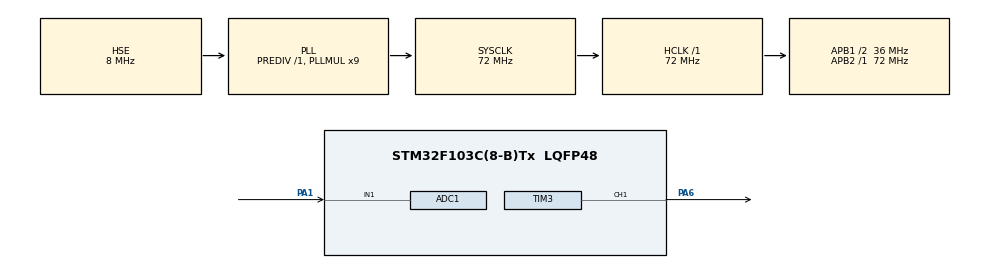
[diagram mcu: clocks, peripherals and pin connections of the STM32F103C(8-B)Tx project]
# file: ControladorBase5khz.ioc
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ADC1.Channel-1\#ChannelRegularConversion=ADC_CHANNEL_1
ADC1.ExternalTrigConv=ADC_EXTERNALTRIGCONV_T3_TRGO
ADC1.NbrOfConversionFlag=1
ADC1.Rank-1\#ChannelRegularConversion=1
ADC1.SamplingTime-1\#ChannelRegularConversion=ADC_SAMPLETIME_13CYCLES_5
ADC1.master=1
Dma.ADC1.1.Direction=DMA_PERIPH_TO_MEMORY
Dma.ADC1.1.Instance=DMA1_Channel1
Dma.ADC1.1.MemDataAlignment=DMA_MDATAALIGN_HALFWORD
Dma.ADC1.1.MemInc=DMA_MINC_ENABLE
Dma.ADC1.1.Mode=DMA_CIRCULAR
Dma.ADC1.1.PeriphDataAlignment=DMA_PDATAALIGN_HALFWORD
Dma.ADC1.1.PeriphInc=DMA_PINC_DISABLE
Dma.ADC1.1.Priority=DMA_PRIORITY_LOW
Dma.Request0=TIM3_CH1/TRIG
Dma.Request1=ADC1
Dma.TIM3_CH1/TRIG.0.Direction=DMA_MEMORY_TO_PERIPH
Dma.TIM3_CH1/TRIG.0.Instance=DMA1_Channel6
Dma.TIM3_CH1/TRIG.0.MemDataAlignment=DMA_MDATAALIGN_HALFWORD
Dma.TIM3_CH1/TRIG.0.MemInc=DMA_MINC_ENABLE
Dma.TIM3_CH1/TRIG.0.Mode=DMA_CIRCULAR
Dma.TIM3_CH1/TRIG.0.PeriphDataAlignment=DMA_PDATAALIGN_HALFWORD
Dma.TIM3_CH1/TRIG.0.PeriphInc=DMA_PINC_DISABLE
Dma.TIM3_CH1/TRIG.0.Priority=DMA_PRIORITY_LOW
Mcu.Family=STM32F1
Mcu.Name=STM32F103C(8-B)Tx
Mcu.Package=LQFP48
NVIC.DMA1_Channel1_IRQn=true\:0\:0\:false\:false\:true\:false\:true\:true
NVIC.DMA1_Channel6_IRQn=true\:0\:0\:false\:false\:true\:false\:true\:true
NVIC.PriorityGroup=NVIC_PRIORITYGROUP_4
PA1.Signal=ADCx_IN1
PA13.Mode=Serial_Wire
PA13.Signal=SYS_JTMS-SWDIO
PA14.Mode=Serial_Wire
PA14.Signal=SYS_JTCK-SWCLK
PA6.Signal=S_TIM3_CH1
PD0-OSC_IN.Mode=HSE-External-Oscillator
PD0-OSC_IN.Signal=RCC_OSC_IN
PD1-OSC_OUT.Mode=HSE-External-Oscillator
PD1-OSC_OUT.Signal=RCC_OSC_OUT
ProjectManager.HeapSize=0x200
ProjectManager.StackSize=0x400
ProjectManager.TargetToolchain=CMake
RCC.ADCPresc=RCC_ADCPCLK2_DIV6
RCC.AHBFreq_Value=72000000
RCC.APB1CLKDivider=RCC_HCLK_DIV2
RCC.APB1Freq_Value=36000000
RCC.APB1TimFreq_Value=72000000
RCC.APB2Freq_Value=72000000
RCC.APB2TimFreq_Value=72000000
RCC.HCLKFreq_Value=72000000
RCC.PLLMUL=RCC_PLL_MUL9
RCC.PLLSourceVirtual=RCC_PLLSOURCE_HSE
RCC.SYSCLKFreq_VALUE=72000000
RCC.SYSCLKSource=RCC_SYSCLKSOURCE_PLLCLK
RCC.USBFreq_Value=72000000
SH.ADCx_IN1.0=ADC1_IN1,IN1
SH.S_TIM3_CH1.0=TIM3_CH1,PWM Generation1 CH1
TIM3.AutoReloadPreload=TIM_AUTORELOAD_PRELOAD_ENABLE
TIM3.Channel-PWM\ Generation1\ CH1=TIM_CHANNEL_1
TIM3.Period=14399
TIM3.TIM_MasterOutputTrigger=TIM_TRGO_UPDATE
VP_TIM3_VS_ClockSourceINT.Mode=Internal
board=custom

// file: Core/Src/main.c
/* USER CODE BEGIN Header */
/**
  ******************************************************************************
  * @file           : main.c
  * @brief          : Main program body
  ******************************************************************************
  * @attention
  *
  * Copyright (c) 2026 STMicroelectronics.
  * All rights reserved.
  *
  * This software is licensed under terms that can be found in the LICENSE file
  * in the root directory of this software component.
  * If no LICENSE file comes with this software, it is provided AS-IS.
  *
  ******************************************************************************
  */
/* USER CODE END Header */
#include "main.h"

ADC_HandleTypeDef hadc1;
DMA_HandleTypeDef hdma_adc1;

TIM_HandleTypeDef htim3;
DMA_HandleTypeDef hdma_tim3_ch1_trig;

/* USER CODE BEGIN PV */
#define PWM_BUF_SIZE 1
volatile uint16_t adc_value = 0;
uint16_t pwm_duty_buffer[PWM_BUF_SIZE] = {0}; // PWM começa em LOW (0)

// Variáveis do Controlador PI
volatile float u = 0.0f;     // u[k]
volatile float u_1 = 0.0f;   // u[k-1]
volatile float e = 0.0f;     // e[k]
volatile float e_1 = 0.0f;   // e[k-1]
volatile float y = 0.0f;     // Tensão medida

// Coeficientes do PI
const float b0 = 0.000358f;
const float b1 = 0.000347f;

// Referência e Lógica de Estado
volatile float Vref = 25.0f;
const float tensao_maxima_sensor = 50.0f; // Ajuste para a tensão máxima do seu sensor

volatile uint8_t degrau_aplicado = 0;
const uint32_t t_milisegundos = 30000; // Tempo em ms até somar 10V (Ex: 2s)
/* USER CODE END PV */

void SystemClock_Config(void);
static void MX_GPIO_Init(void);
static void MX_DMA_Init(void);
static void MX_TIM3_Init(void);
static void MX_ADC1_Init(void);

int main(void)
{

  /* MCU Configuration--------------------------------------------------------*/

  /* Reset of all peripherals, Initializes the Flash interface and the Systick. */
  HAL_Init();

  /* Configure the system clock */
  SystemClock_Config();

  /* Initialize all configured peripherals */
  MX_GPIO_Init();
  MX_DMA_Init();
  MX_TIM3_Init();
  MX_ADC1_Init();
  /* USER CODE BEGIN 2 */
  // Passa o endereço da variável única e define o tamanho como 1
  HAL_ADC_Start_DMA(&hadc1, (uint32_t*)&adc_value, 1);
  // Inicia a geração do PWM via DMA
  HAL_TIM_PWM_Start_DMA(&htim3, TIM_CHANNEL_1, (uint32_t*)pwm_duty_buffer, PWM_BUF_SIZE);
  /* USER CODE END 2 */

  /* Infinite loop */
  while (1)
  {
    if (!degrau_aplicado && HAL_GetTick() >= t_milisegundos) {
      Vref += 10.0f; // Sobe de 25V para 35V
      degrau_aplicado = 1; // Trava para executar apenas uma vez
    }
  }
}

void SystemClock_Config(void)
{
  RCC_OscInitTypeDef RCC_OscInitStruct = {0};
  RCC_ClkInitTypeDef RCC_ClkInitStruct = {0};
  RCC_PeriphCLKInitTypeDef PeriphClkInit = {0};

  /** Initializes the RCC Oscillators according to the specified parameters
  * in the RCC_OscInitTypeDef structure.
  */
  RCC_OscInitStruct.OscillatorType = RCC_OSCILLATORTYPE_HSE;
  RCC_OscInitStruct.HSEState = RCC_HSE_ON;
  RCC_OscInitStruct.HSEPredivValue = RCC_HSE_PREDIV_DIV1;
  RCC_OscInitStruct.HSIState = RCC_HSI_ON;
  RCC_OscInitStruct.PLL.PLLState = RCC_PLL_ON;
  RCC_OscInitStruct.PLL.PLLSource = RCC_PLLSOURCE_HSE;
  RCC_OscInitStruct.PLL.PLLMUL = RCC_PLL_MUL9;
  if (HAL_RCC_OscConfig(&RCC_OscInitStruct) != HAL_OK)
  {
    Error_Handler();
  }

  /** Initializes the CPU, AHB and APB buses clocks
  */
  RCC_ClkInitStruct.ClockType = RCC_CLOCKTYPE_HCLK|RCC_CLOCKTYPE_SYSCLK
                              |RCC_CLOCKTYPE_PCLK1|RCC_CLOCKTYPE_PCLK2;
  RCC_ClkInitStruct.SYSCLKSource = RCC_SYSCLKSOURCE_PLLCLK;
  RCC_ClkInitStruct.AHBCLKDivider = RCC_SYSCLK_DIV1;
  RCC_ClkInitStruct.APB1CLKDivider = RCC_HCLK_DIV2;
  RCC_ClkInitStruct.APB2CLKDivider = RCC_HCLK_DIV1;

  if (HAL_RCC_ClockConfig(&RCC_ClkInitStruct, FLASH_LATENCY_2) != HAL_OK)
  {
    Error_Handler();
  }
  PeriphClkInit.PeriphClockSelection = RCC_PERIPHCLK_ADC;
  PeriphClkInit.AdcClockSelection = RCC_ADCPCLK2_DIV6;
  if (HAL_RCCEx_PeriphCLKConfig(&PeriphClkInit) != HAL_OK)
  {
    Error_Handler();
  }
}

static void MX_ADC1_Init(void)
{

  ADC_ChannelConfTypeDef sConfig = {0};

  /** Common config
  */
  hadc1.Instance = ADC1;
  hadc1.Init.ScanConvMode = ADC_SCAN_DISABLE;
  hadc1.Init.ContinuousConvMode = DISABLE;
  hadc1.Init.DiscontinuousConvMode = DISABLE;
  hadc1.Init.ExternalTrigConv = ADC_EXTERNALTRIGCONV_T3_TRGO;
  hadc1.Init.DataAlign = ADC_DATAALIGN_RIGHT;
  hadc1.Init.NbrOfConversion = 1;
  if (HAL_ADC_Init(&hadc1) != HAL_OK)
  {
    Error_Handler();
  }

  /** Configure Regular Channel
  */
  sConfig.Channel = ADC_CHANNEL_1;
  sConfig.Rank = ADC_REGULAR_RANK_1;
  sConfig.SamplingTime = ADC_SAMPLETIME_13CYCLES_5;
  if (HAL_ADC_ConfigChannel(&hadc1, &sConfig) != HAL_OK)
  {
    Error_Handler();
  }

}

static void MX_TIM3_Init(void)
{

  TIM_ClockConfigTypeDef sClockSourceConfig = {0};
  TIM_MasterConfigTypeDef sMasterConfig = {0};
  TIM_OC_InitTypeDef sConfigOC = {0};

  htim3.Instance = TIM3;
  htim3.Init.Prescaler = 0;
  htim3.Init.CounterMode = TIM_COUNTERMODE_UP;
  htim3.Init.Period = 14399;
  htim3.Init.ClockDivision = TIM_CLOCKDIVISION_DIV1;
  htim3.Init.AutoReloadPreload = TIM_AUTORELOAD_PRELOAD_ENABLE;
  if (HAL_TIM_Base_Init(&htim3) != HAL_OK)
  {
    Error_Handler();
  }
  sClockSourceConfig.ClockSource = TIM_CLOCKSOURCE_INTERNAL;
  if (HAL_TIM_ConfigClockSource(&htim3, &sClockSourceConfig) != HAL_OK)
  {
    Error_Handler();
  }
  if (HAL_TIM_PWM_Init(&htim3) != HAL_OK)
  {
    Error_Handler();
  }
  sMasterConfig.MasterOutputTrigger = TIM_TRGO_UPDATE;
  sMasterConfig.MasterSlaveMode = TIM_MASTERSLAVEMODE_DISABLE;
  if (HAL_TIMEx_MasterConfigSynchronization(&htim3, &sMasterConfig) != HAL_OK)
  {
    Error_Handler();
  }
  sConfigOC.OCMode = TIM_OCMODE_PWM1;
  sConfigOC.Pulse = 0;
  sConfigOC.OCPolarity = TIM_OCPOLARITY_HIGH;
  sConfigOC.OCFastMode = TIM_OCFAST_DISABLE;
  if (HAL_TIM_PWM_ConfigChannel(&htim3, &sConfigOC, TIM_CHANNEL_1) != HAL_OK)
  {
    Error_Handler();
  }
  HAL_TIM_MspPostInit(&htim3);

}

static void MX_DMA_Init(void)
{

  /* DMA controller clock enable */
  __HAL_RCC_DMA1_CLK_ENABLE();

  /* DMA interrupt init */
  /* DMA1_Channel1_IRQn interrupt configuration */
  HAL_NVIC_SetPriority(DMA1_Channel1_IRQn, 0, 0);
  HAL_NVIC_EnableIRQ(DMA1_Channel1_IRQn);
  /* DMA1_Channel6_IRQn interrupt configuration */
  HAL_NVIC_SetPriority(DMA1_Channel6_IRQn, 0, 0);
  HAL_NVIC_EnableIRQ(DMA1_Channel6_IRQn);

}

static void MX_GPIO_Init(void)
{

  /* GPIO Ports Clock Enable */
  __HAL_RCC_GPIOD_CLK_ENABLE();
  __HAL_RCC_GPIOA_CLK_ENABLE();

}

/* USER CODE BEGIN 4 */
/* USER CODE BEGIN 4 */
void HAL_ADC_ConvCpltCallback(ADC_HandleTypeDef* hadc) {
    if (hadc->Instance == ADC1) {
        // --- 1. LER A ENTRADA ---
        // Converte o valor bruto do DMA para tensão (0 a tensao_maxima_sensor)
        y = ((float)adc_value / 4095.0f) * tensao_maxima_sensor;

        // --- 2. RESOLVER AS EQUAÇÕES ---
        e = Vref - y;
        u = u_1 + (b0 * e) + (b1 * e_1);

        // Saturação (Anti-Windup intrínseco pela limitação de u)
        if (u > 1.0f) {
            u = 1.0f;
        } else if (u < 0.0f) {
            u = 0.0f;
        }

        // --- 3. ATUALIZAR A SAÍDA ---
        // Multiplica o esforço (0 a 1) pelo ARR (14399) e atualiza o buffer do DMA
        pwm_duty_buffer[0] = (uint16_t)(u * 14399.0f);

        // --- 4. ATUALIZAR ESTADOS PASSADOS ---
        u_1 = u;
        e_1 = e;
    }
}
/* USER CODE END 4 */
/* USER CODE END 4 */

void Error_Handler(void)
{
  __disable_irq();
  while (1)
  {
  }
}
